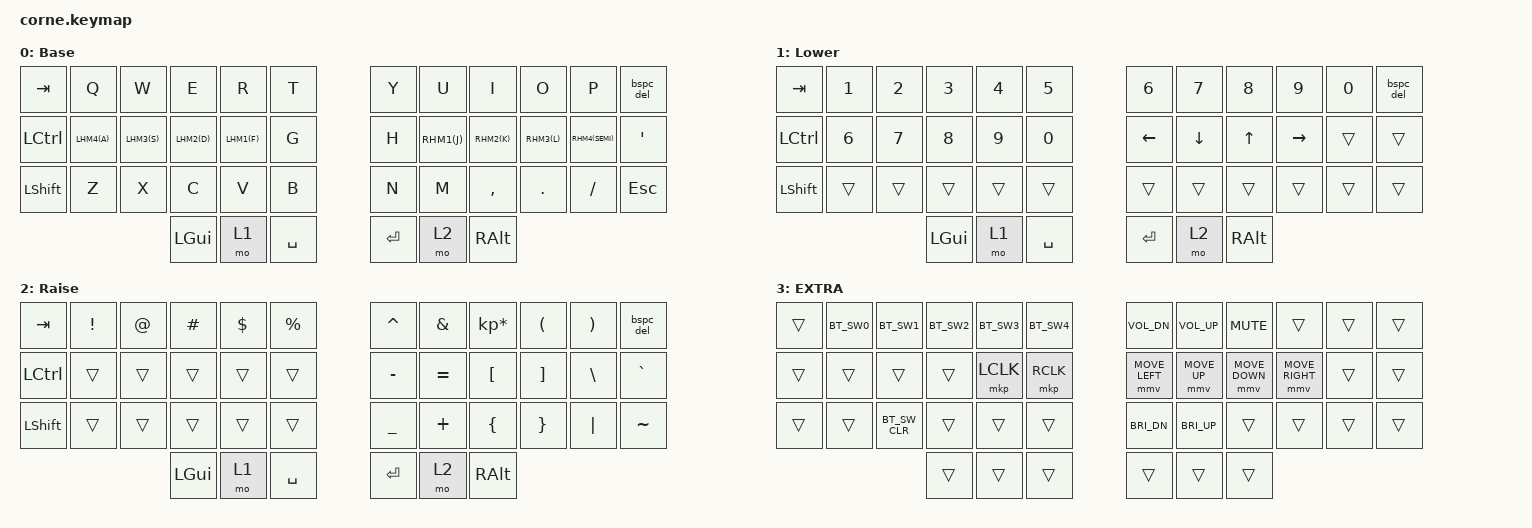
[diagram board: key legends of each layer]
/*
 * Copyright (c) 2020 The ZMK Contributors
 *
 * SPDX-License-Identifier: MIT
 */

#include <behaviors.dtsi>
#include <dt-bindings/zmk/keys.h>
#include <dt-bindings/zmk/bt.h>
#include <dt-bindings/zmk/pointing.h>

#include "keys.dtsi"
#include "homerowmods.dtsi"
#include "bluetooth.dtsi"


/ {
	behaviors {
		bspc_del: bspc_del {
			compatible = "zmk,behavior-mod-morph";
			#binding-cells = <0>;
			bindings = <&kp BSPC>, <&kp BSPC>;
			//bindings = <&kp BSPC>, <&kp DEL>;
			mods = <(MOD_LSFT|MOD_RSFT)>;
		};
	};
};

/ {
        keymap {
                compatible = "zmk,keymap";

                default_layer {
// -----------------------------------------------------------------------------------------
// |  TAB |  Q  |  W  |  E  |  R  |  T  |   |  Y  |  U   |  I  |  O  |  P  | BKSP |
// | CTRL |  A  |  S  |  D  |  F  |  G  |   |  H  |  J   |  K  |  L  |  ;  |  '   |
// | SHFT |  Z  |  X  |  C  |  V  |  B  |   |  N  |  M   |  ,  |  .  |  /  | ESC  |
//                    | GUI | LWR | SPC |   | ENT | RSE  | ALT |
                        display-name = "Base";
                        bindings = <
   &kp TAB   &kp Q &kp W &kp E &kp R   &kp T   &kp Y &kp U  &kp I     &kp O   &kp P    &bspc_del
   &kp LCTRL LHM4(A) LHM3(S) LHM2(D) LHM1(F) &kp G   &kp H RHM1(J)  RHM2(K)     RHM3(L)   RHM4(SEMI) &kp SQT
   &kp LSHFT &kp Z &kp X &kp C &kp V   &kp B   &kp N &kp M  &kp COMMA &kp DOT &kp FSLH &kp ESC
                  &kp LGUI &mo 1  &kp SPACE   &kp RET &mo 2 &kp RALT
                        >;
                };
                lower_layer {
// -----------------------------------------------------------------------------------------
// |  TAB |  1  |  2  |  3  |  4  |  5  |   |  6  |  7  |  8  |  9  |  0  | BKSP |
// | CTRL |     |     |     |     |     |   | LFT | DWN |  UP | RGT |     |      |
// | SHFT |     |     |     |     |     |   |     |     |     |     |     |      |
//                    | GUI |     | SPC |   | ENT |     | ALT |
                        display-name = "Lower";
                        bindings = <
   &kp TAB   &kp N1 &kp N2 &kp N3   &kp N4 &kp N5     &kp N6   &kp N7   &kp N8 &kp N9    &kp N0 &bspc_del
   &kp LCTRL &kp N6 &kp N7 &kp N8   &kp N9 &kp N0     &kp LEFT &kp DOWN &kp UP &kp RIGHT &trans &trans
   &kp LSHFT &trans &trans &trans   &trans &trans     &trans   &trans   &trans &trans    &trans &trans
                           &kp LGUI &mo 1  &kp SPACE  &kp RET  &mo 2    &kp RALT
                        >;
                };

                raise_layer {
// -----------------------------------------------------------------------------------------
// |  TAB |  !  |  @  |  #  |  $  |  %  |   |  ^  |  &  |  *  |  (  |  )  | BKSP |
// | CTRL |     |     |     |     |     |   |  -  |  =  |  [  |  ]  |  \  |  `   |
// | SHFT |     |     |     |     |     |   |  _  |  +  |  {  |  }  | "|" |  ~   |
//                    | GUI |     | SPC |   | ENT |     | ALT |
                        display-name = "Raise";
                        bindings = <
   &kp TAB   &kp EXCL &kp AT &kp HASH &kp DLLR &kp PRCNT  &kp CARET &kp AMPS  &kp KP_MULTIPLY &kp LPAR &kp RPAR &bspc_del
   &kp LCTRL &trans   &trans &trans   &trans   &trans     &kp MINUS &kp EQUAL &kp LBKT        &kp RBKT &kp BSLH &kp GRAVE
   &kp LSHFT &trans   &trans &trans   &trans   &trans     &kp UNDER &kp PLUS  &kp LBRC        &kp RBRC &kp PIPE &kp TILDE
                               &kp LGUI &mo 1 &kp SPACE   &kp RET &mo 2 &kp RALT
                        >;
                };

		extra_layer {
		    display-name = "EXTRA";
		    bindings = <
	&trans BT_SW0 BT_SW1    BT_SW2 BT_SW3    BT_SW4       &kp C_VOL_DN   &kp C_VOL_UP &kp C_MUTE     &trans          &trans &trans
	&trans &trans &trans    &trans &mkp LCLK &mkp RCLK    &mmv MOVE_LEFT &mmv MOVE_UP &mmv MOVE_DOWN &mmv MOVE_RIGHT &trans &trans
	&trans &trans BT_SW_CLR &trans &trans    &trans       &kp C_BRI_DN   &kp C_BRI_UP &trans 		 &trans 	     &trans &trans
			                &trans &trans    &trans       &trans &trans &trans
		    >;
		};
	};

	conditional_layers {
		compatible = "zmk,conditional-layers";
		tri_layer {
		    if-layers = <1 2>;
		    then-layer = <3>;
		};
	};
};
